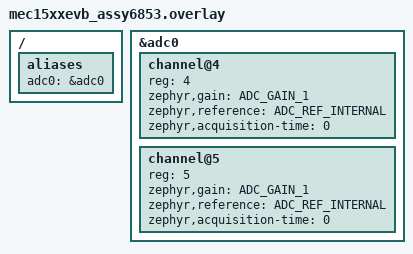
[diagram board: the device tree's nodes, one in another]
/*
 * Copyright (c) 2024 Centro de Inovacao EDGE
 *
 * SPDX-License-Identifier: Apache-2.0
 */

/ {
	aliases {
		adc0 = &adc0;
	};
};

&adc0 {
	#address-cells = <1>;
	#size-cells = <0>;

	channel@4 {
		reg = <4>;
		zephyr,gain = "ADC_GAIN_1";
		zephyr,reference = "ADC_REF_INTERNAL";
		zephyr,acquisition-time = <0>;
	};

	channel@5 {
		reg = <5>;
		zephyr,gain = "ADC_GAIN_1";
		zephyr,reference = "ADC_REF_INTERNAL";
		zephyr,acquisition-time = <0>;
	};
};
